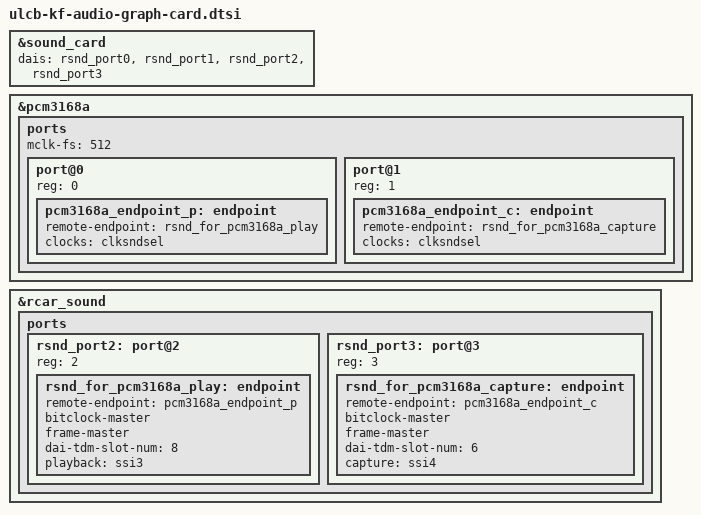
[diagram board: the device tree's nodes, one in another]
&sound_card {
	dais = <&rsnd_port0  
		&rsnd_port1  
		&rsnd_port2  
		&rsnd_port3  
		>;
};
&pcm3168a {
	ports {
		#address-cells = <1>;
		#size-cells = <0>;
		mclk-fs = <512>;
		port@0 {
			reg = <0>;
			pcm3168a_endpoint_p: endpoint {
				remote-endpoint = <&rsnd_for_pcm3168a_play>;
				clocks = <&clksndsel>;
			};
		};
		port@1 {
			reg = <1>;
			pcm3168a_endpoint_c: endpoint {
				remote-endpoint = <&rsnd_for_pcm3168a_capture>;
				clocks = <&clksndsel>;
			};
		};
	};
};
&rcar_sound {
	ports {
		rsnd_port2: port@2 {
			reg = <2>;
			rsnd_for_pcm3168a_play: endpoint {
				remote-endpoint = <&pcm3168a_endpoint_p>;
				bitclock-master;
				frame-master;
				dai-tdm-slot-num = <8>;
				playback = <&ssi3>;
			};
		};
		rsnd_port3: port@3 {
			reg = <3>;
			rsnd_for_pcm3168a_capture: endpoint {
				remote-endpoint = <&pcm3168a_endpoint_c>;
				bitclock-master;
				frame-master;
				dai-tdm-slot-num = <6>;
				capture = <&ssi4>;
			};
		};
	};
};
